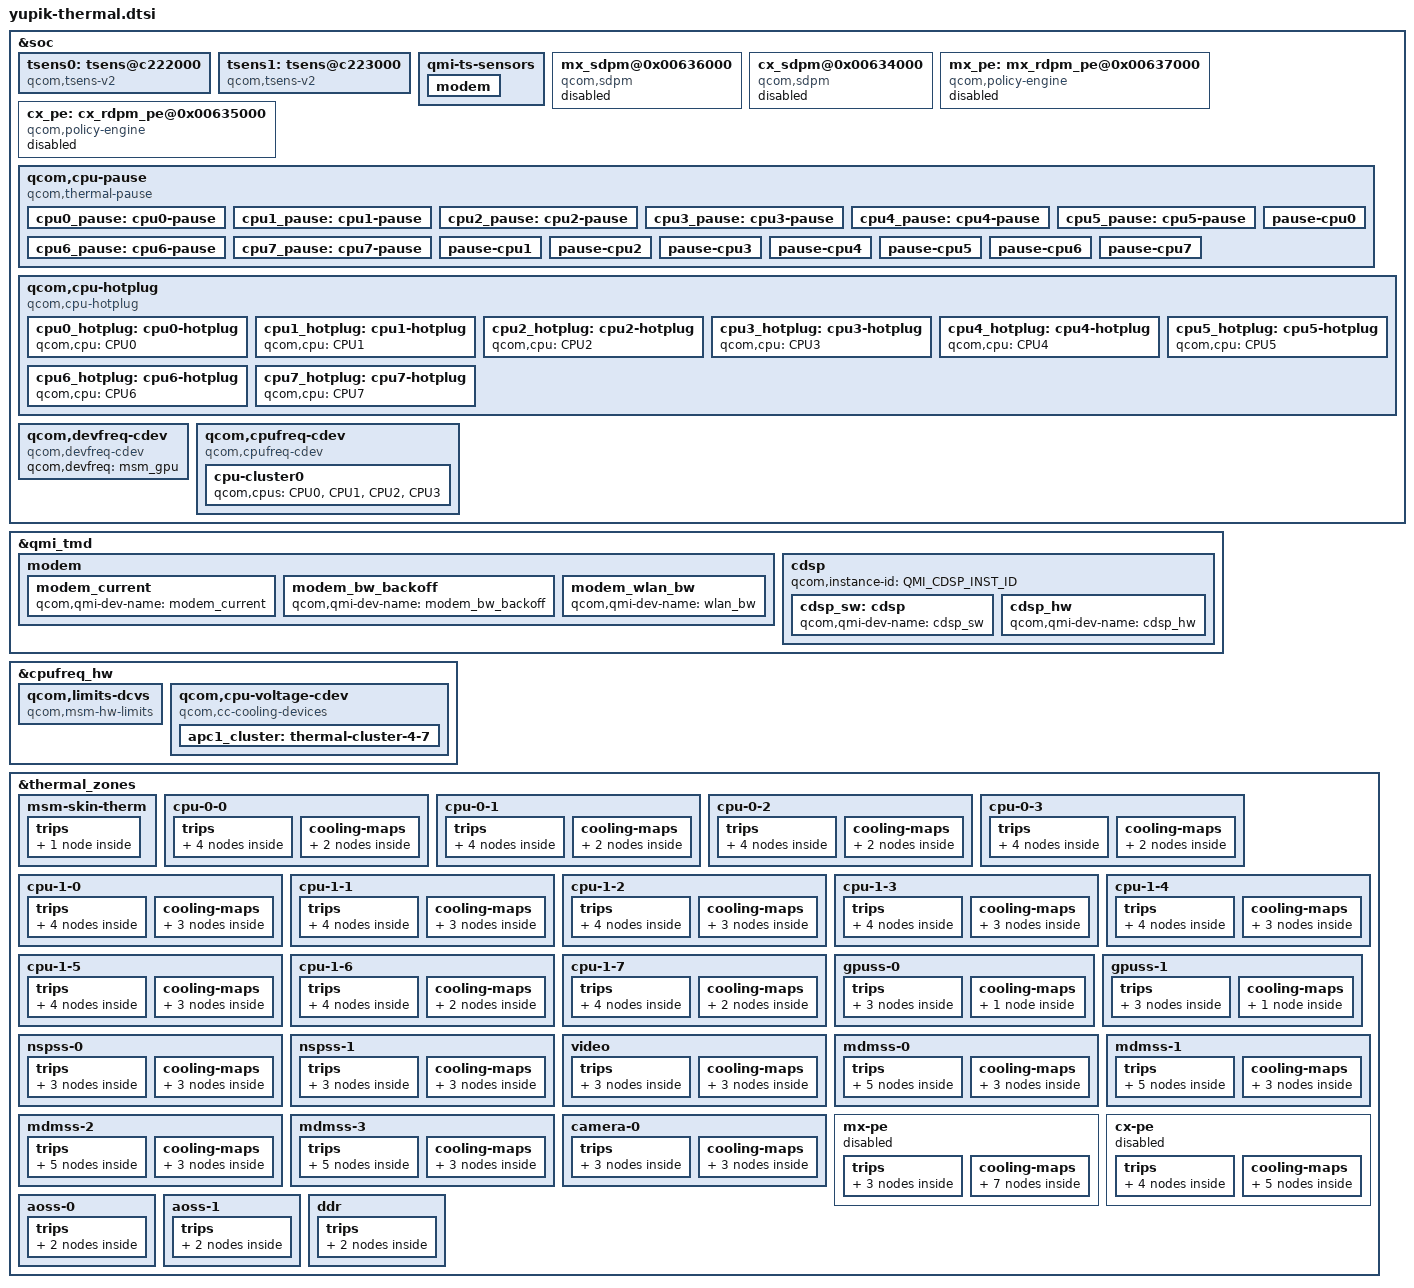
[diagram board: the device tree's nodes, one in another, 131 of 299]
// SPDX-License-Identifier: BSD-3-Clause
/*
 * Copyright (c) Qualcomm Technologies, Inc. and/or its subsidiaries.
 */

#include <dt-bindings/thermal/thermal_qti.h>
#include "lahaina-thermal-modem.dtsi"

&soc {
	tsens0:tsens@c222000 {
		compatible = "qcom,tsens-v2";
		reg = <0x0C263000 0x1ff>,
				<0x0C222000 0x8>;
		#qcom,sensors = <16>;
		interrupts = <GIC_SPI 506 IRQ_TYPE_LEVEL_HIGH>,
				<GIC_SPI 508 IRQ_TYPE_LEVEL_HIGH>;
		interrupt-names = "uplow","critical";
		#thermal-sensor-cells = <1>;
		nvmem-cells = <&tsens_chipinfo>;
		nvmem-cell-names = "tsens_chipinfo";
	};

	tsens1:tsens@c223000 {
		compatible = "qcom,tsens-v2";
		reg = <0x0C265000 0x1ff>,
				<0x0C223000 0x8>;
		#qcom,sensors = <16>;
		interrupts = <GIC_SPI 507 IRQ_TYPE_LEVEL_HIGH>,
				<GIC_SPI 509 IRQ_TYPE_LEVEL_HIGH>;
		interrupt-names = "uplow","critical";
		#thermal-sensor-cells = <1>;
		nvmem-cells = <&tsens_chipinfo>;
		nvmem-cell-names = "tsens_chipinfo";
	};

	qmi-ts-sensors {
		modem {
			qcom,qmi-sensor-names = "pa",
						"pa_1",
						"qfe_wtr0",
						"modem_tsens",
						"qfe_mmw0",
						"qfe_mmw1",
						"qfe_mmw2",
						"qfe_mmw3",
						"xo_therm",
						"qfe_mmw_streamer0",
						"qfe_mmw0_mod",
						"qfe_mmw1_mod",
						"qfe_mmw2_mod",
						"qfe_mmw3_mod",
						"qfe_ret_pa0",
						"qfe_wtr_pa0",
						"qfe_wtr_pa1",
						"qfe_wtr_pa2",
						"qfe_wtr_pa3",
						"sys_therm1",
						"modem_tsens1",
						"mmw_pa1",
						"mmw_pa2",
						"mmw_pa3",
						"msm_skin_therm";
		};
	};

	mx_sdpm@0x00636000 {
		compatible = "qcom,sdpm";
		reg = <0x00636000 0x1000>;
		clock-names = "cam_cc_ipe", "disp_cc_mdss_mdp";
		clocks = <&camcc CAM_CC_IPE_0_CLK_SRC>,
			<&dispcc DISP_CC_MDSS_MDP_CLK_SRC>;
		cam_cc_ipe-supply = <&cam_cc_ipe_0_gdsc>;
		csr-id = <1 4>;
		status = "disabled";
	};

	cx_sdpm@0x00634000 {
		compatible = "qcom,sdpm";
		reg = <0x00634000 0x1000>;
		clock-names = "cam_cc_ipe", "disp_cc_mdss_mdp";
		clocks = <&camcc CAM_CC_IPE_0_CLK_SRC>,
			<&dispcc DISP_CC_MDSS_MDP_CLK_SRC>;
		cam_cc_ipe-supply = <&cam_cc_ipe_0_gdsc>;
		csr-id = <0 2>;
		status = "disabled";
	};

	mx_pe: mx_rdpm_pe@0x00637000 {
		compatible = "qcom,policy-engine";
		#thermal-sensor-cells = <0>;
		reg = <0x00637000 0x1000>;
		interrupts = <GIC_SPI 237 IRQ_TYPE_LEVEL_HIGH>;
		status = "disabled";
	};

	cx_pe: cx_rdpm_pe@0x00635000 {
		compatible = "qcom,policy-engine";
		#thermal-sensor-cells = <0>;
		reg = <0x00635000 0x1000>;
		interrupts = <GIC_SPI 243 IRQ_TYPE_LEVEL_HIGH>;
		status = "disabled";
	};

	qcom,cpu-pause {
		compatible = "qcom,thermal-pause";
		cpu0_pause: cpu0-pause {

			qcom,cpus = <&CPU0>;
			qcom,cdev-alias = "thermal-pause-1";
			#cooling-cells = <2>;
		};

		cpu1_pause: cpu1-pause {
			qcom,cpus = <&CPU1>;
			qcom,cdev-alias = "thermal-pause-2";
			#cooling-cells = <2>;
		};

		cpu2_pause: cpu2-pause {
			qcom,cpus = <&CPU2>;
			qcom,cdev-alias = "thermal-pause-4";
			#cooling-cells = <2>;
		};

		cpu3_pause: cpu3-pause {
			qcom,cpus = <&CPU3>;
			qcom,cdev-alias = "thermal-pause-8";
			#cooling-cells = <2>;
		};

		cpu4_pause: cpu4-pause {
			qcom,cpus = <&CPU4>;
			qcom,cdev-alias = "thermal-pause-10";
			#cooling-cells = <2>;
		};

		cpu5_pause: cpu5-pause {
			qcom,cpus = <&CPU5>;
			qcom,cdev-alias = "thermal-pause-20";
			#cooling-cells = <2>;
		};

		cpu6_pause: cpu6-pause {
			qcom,cpus = <&CPU6>;
			qcom,cdev-alias = "thermal-pause-40";
			#cooling-cells = <2>;
		};

		cpu7_pause: cpu7-pause {
			qcom,cpus = <&CPU7>;
			qcom,cdev-alias = "thermal-pause-80";
			#cooling-cells = <2>;
		};

		/* Thermal-engine cooling devices */
		pause-cpu0 {
			qcom,cpus = <&CPU0>;
			qcom,cdev-alias = "pause-cpu0";
		};

		pause-cpu1 {
			qcom,cpus = <&CPU1>;
			qcom,cdev-alias = "pause-cpu1";
		};

		pause-cpu2 {
			qcom,cpus = <&CPU2>;
			qcom,cdev-alias = "pause-cpu2";
		};

		pause-cpu3 {
			qcom,cpus = <&CPU3>;
			qcom,cdev-alias = "pause-cpu3";
		};

		pause-cpu4 {
			qcom,cpus = <&CPU4>;
			qcom,cdev-alias = "pause-cpu4";
		};

		pause-cpu5 {
			qcom,cpus = <&CPU5>;
			qcom,cdev-alias = "pause-cpu5";
		};

		pause-cpu6 {
			qcom,cpus = <&CPU6>;
			qcom,cdev-alias = "pause-cpu6";
		};

		pause-cpu7 {
			qcom,cpus = <&CPU7>;
			qcom,cdev-alias = "pause-cpu7";
		};
	};

	qcom,cpu-hotplug {
		compatible = "qcom,cpu-hotplug";
		cpu0_hotplug: cpu0-hotplug {
			qcom,cpu = <&CPU0>;
			#cooling-cells = <2>;
		};

		cpu1_hotplug: cpu1-hotplug {
			qcom,cpu = <&CPU1>;
			#cooling-cells = <2>;
		};

		cpu2_hotplug: cpu2-hotplug {
			qcom,cpu = <&CPU2>;
			#cooling-cells = <2>;
		};

		cpu3_hotplug: cpu3-hotplug {
			qcom,cpu = <&CPU3>;
			#cooling-cells = <2>;
		};

		cpu4_hotplug: cpu4-hotplug {
			qcom,cpu = <&CPU4>;
			#cooling-cells = <2>;
		};

		cpu5_hotplug: cpu5-hotplug {
			qcom,cpu = <&CPU5>;
			#cooling-cells = <2>;
		};

		cpu6_hotplug: cpu6-hotplug {
			qcom,cpu = <&CPU6>;
			#cooling-cells = <2>;
		};

		cpu7_hotplug: cpu7-hotplug {
			qcom,cpu = <&CPU7>;
			#cooling-cells = <2>;
		};
	};

	qcom,devfreq-cdev {
		compatible = "qcom,devfreq-cdev";
		qcom,devfreq = <&msm_gpu>;
	};

	qcom,cpufreq-cdev {
		compatible = "qcom,cpufreq-cdev";
		cpu-cluster0 {
			qcom,cpus = <&CPU0 &CPU1 &CPU2 &CPU3>;
		};
	};
};

&qmi_tmd {
	modem {
		modem_current: modem_current {
			qcom,qmi-dev-name = "modem_current";
			#cooling-cells = <2>;
		};

		modem_bw_backoff: modem_bw_backoff {
			qcom,qmi-dev-name = "modem_bw_backoff";
			#cooling-cells = <2>;
		};

		modem_wlan_bw: modem_wlan_bw {
			qcom,qmi-dev-name = "wlan_bw";
			#cooling-cells = <2>;
		};
	};

	cdsp {
		qcom,instance-id = <QMI_CDSP_INST_ID>;

		cdsp_sw: cdsp {
			qcom,qmi-dev-name = "cdsp_sw";
			#cooling-cells = <2>;
		};

		cdsp_hw: cdsp_hw {
			qcom,qmi-dev-name = "cdsp_hw";
			#cooling-cells = <2>;
		};
	};
};

&cpufreq_hw {
	qcom,limits-dcvs {
		compatible = "qcom,msm-hw-limits";
		isens_vref_0p8-supply = <&pm8350c_l10_ao>;
		isens-vref-0p8-settings = <880000 880000 30000>;
		isens_vref_1p8-supply = <&pm8350c_l1_ao>;
		isens-vref-1p8-settings = <1800000 1800000 20000>;
	};

	qcom,cpu-voltage-cdev {
		compatible = "qcom,cc-cooling-devices";
		apc1_cluster: thermal-cluster-4-7 {
			qcom,cluster0 = <&CPU4 &CPU5 &CPU6>;
			qcom,cluster1 = <&CPU7>;
			#cooling-cells = <2>;
		};
	};
};

&thermal_zones {
	/delete-node/ modem-sdr-mmw-usr;
	/delete-node/ modem-ambient-usr;
	/delete-node/ mdmss-1;
	/delete-node/ mdmss-2;

	msm-skin-therm {
		polling-delay-passive = <0>;
		polling-delay = <0>;
		thermal-sensors = <&qmi_sensor
				(QMI_MODEM_INST_ID+QMI_QTM_THERM)>;
		trips {
			active-config0 {
				temperature = <125000>;
				hysteresis = <1000>;
				type = "passive";
			};
		};
	};

	cpu-0-0 {
		polling-delay-passive = <0>;
		polling-delay = <0>;
		thermal-sensors = <&tsens0 1>;
		trips {
			active-config0 {
				temperature = <125000>;
				hysteresis = <1000>;
				type = "passive";
			};

			reset-mon-cfg {
				temperature = <115000>;
				hysteresis = <5000>;
				type = "passive";
			};

			cpu00_config: cpu00-config {
				temperature = <110000>;
				hysteresis = <10000>;
				type = "passive";
			};

			cpu00_config1: cpu00-config1 {
				temperature = <112000>;
				hysteresis = <12000>;
				type = "passive";
			};
		};

		cooling-maps {
			cpu00_cdev {
				trip = <&cpu00_config>;
				cooling-device = <&cpu0_pause 0 1>;
			};

			cpu00_cdev2 {
				trip = <&cpu00_config1>;
				cooling-device = <&cpu0_hotplug 0 1>;
			};
		};
	};

	cpu-0-1 {
		polling-delay-passive = <0>;
		polling-delay = <0>;
		thermal-sensors = <&tsens0 2>;
		trips {
			active-config0 {
				temperature = <125000>;
				hysteresis = <1000>;
				type = "passive";
			};

			reset-mon-cfg {
				temperature = <115000>;
				hysteresis = <5000>;
				type = "passive";
			};

			cpu01_config: cpu01-config {
				temperature = <110000>;
				hysteresis = <10000>;
				type = "passive";
			};

			cpu01_config1: cpu01-config1 {
				temperature = <112000>;
				hysteresis = <12000>;
				type = "passive";
			};
		};

		cooling-maps {
			cpu01_cdev {
				trip = <&cpu01_config>;
				cooling-device = <&cpu1_pause 0 1>;
			};

			cpu01_cdev2 {
				trip = <&cpu01_config1>;
				cooling-device = <&cpu1_hotplug 0 1>;
			};
		};
	};

	cpu-0-2 {
		polling-delay-passive = <0>;
		polling-delay = <0>;
		thermal-sensors = <&tsens0 3>;
		trips {
			active-config0 {
				temperature = <125000>;
				hysteresis = <1000>;
				type = "passive";
			};

			reset-mon-cfg {
				temperature = <115000>;
				hysteresis = <5000>;
				type = "passive";
			};

			cpu02_config: cpu02-config {
				temperature = <110000>;
				hysteresis = <10000>;
				type = "passive";
			};

			cpu02_config1: cpu02-config1 {
				temperature = <112000>;
				hysteresis = <12000>;
				type = "passive";
			};
		};

		cooling-maps {
			cpu02_cdev {
				trip = <&cpu02_config>;
				cooling-device = <&cpu2_pause 0 1>;
			};

			cpu02_cdev2 {
				trip = <&cpu02_config1>;
				cooling-device = <&cpu2_hotplug 0 1>;
			};
		};
	};

	cpu-0-3 {
		polling-delay-passive = <0>;
		polling-delay = <0>;
		thermal-sensors = <&tsens0 4>;
		trips {
			active-config0 {
				temperature = <125000>;
				hysteresis = <1000>;
				type = "passive";
			};

			reset-mon-cfg {
				temperature = <115000>;
				hysteresis = <5000>;
				type = "passive";
			};

			cpu03_config: cpu03-config {
				temperature = <110000>;
				hysteresis = <10000>;
				type = "passive";
			};

			cpu03_config1: cpu03-config1 {
				temperature = <112000>;
				hysteresis = <12000>;
				type = "passive";
			};
		};

		cooling-maps {
			cpu03_cdev {
				trip = <&cpu03_config>;
				cooling-device = <&cpu3_pause 0 1>;
			};

			cpu03_cdev2 {
				trip = <&cpu03_config1>;
				cooling-device = <&cpu3_hotplug 0 1>;
			};
		};
	};

	cpu-1-0 {
		polling-delay-passive = <0>;
		polling-delay = <0>;
		thermal-sensors = <&tsens0 7>;
		trips {
			active-config0 {
				temperature = <125000>;
				hysteresis = <1000>;
				type = "passive";
			};

			reset-mon-cfg {
				temperature = <115000>;
				hysteresis = <5000>;
				type = "passive";
			};

			cpu10_config: cpu10-config {
				temperature = <108000>;
				hysteresis = <8000>;
				type = "passive";
			};

			cpu10_config1: cpu10-config1 {
				temperature = <110000>;
				hysteresis = <10000>;
				type = "passive";
			};
		};

		cooling-maps {
			cpu10_cdev {
				trip = <&cpu10_config>;
				cooling-device = <&cpu4_pause 0 1>;
			};

			cpu10_cdev1 {
				trip = <&cpu10_config>;
				cooling-device = <&apc1_cluster 0 THERMAL_NO_LIMIT>;
			};

			cpu10_cdev2 {
				trip = <&cpu10_config1>;
				cooling-device = <&cpu4_hotplug 0 1>;
			};
		};
	};

	cpu-1-1 {
		polling-delay-passive = <0>;
		polling-delay = <0>;
		thermal-sensors = <&tsens0 8>;
		trips {
			active-config0 {
				temperature = <125000>;
				hysteresis = <1000>;
				type = "passive";
			};

			reset-mon-cfg {
				temperature = <115000>;
				hysteresis = <5000>;
				type = "passive";
			};

			cpu11_config: cpu11-config {
				temperature = <108000>;
				hysteresis = <8000>;
				type = "passive";
			};

			cpu11_config1: cpu11-config1 {
				temperature = <110000>;
				hysteresis = <10000>;
				type = "passive";
			};
		};

		cooling-maps {
			cpu11_cdev {
				trip = <&cpu11_config>;
				cooling-device = <&cpu4_pause 0 1>;
			};

			cpu11_cdev1 {
				trip = <&cpu11_config>;
				cooling-device = <&apc1_cluster 0 THERMAL_NO_LIMIT>;
			};

			cpu11_cdev2 {
				trip = <&cpu11_config1>;
				cooling-device = <&cpu4_hotplug 0 1>;
			};
		};
	};

	cpu-1-2 {
		polling-delay-passive = <0>;
		polling-delay = <0>;
		thermal-sensors = <&tsens0 9>;
		trips {
			active-config0 {
				temperature = <125000>;
				hysteresis = <1000>;
				type = "passive";
			};

			reset-mon-cfg {
				temperature = <115000>;
				hysteresis = <5000>;
				type = "passive";
			};

			cpu12_config: cpu12-config {
				temperature = <108000>;
				hysteresis = <8000>;
				type = "passive";
			};

			cpu12_config1: cpu12-config1 {
				temperature = <110000>;
				hysteresis = <10000>;
				type = "passive";
			};
		};

		cooling-maps {
			cpu12_cdev {
				trip = <&cpu12_config>;
				cooling-device = <&cpu5_pause 0 1>;
			};

			cpu12_cdev1 {
				trip = <&cpu12_config>;
				cooling-device = <&apc1_cluster 0 THERMAL_NO_LIMIT>;
			};

			cpu12_cdev2 {
				trip = <&cpu12_config1>;
				cooling-device = <&cpu5_hotplug 0 1>;
			};
		};
	};

	cpu-1-3 {
		polling-delay-passive = <0>;
		polling-delay = <0>;
		thermal-sensors = <&tsens0 10>;
		trips {
			active-config0 {
				temperature = <125000>;
				hysteresis = <1000>;
				type = "passive";
			};

			reset-mon-cfg {
				temperature = <115000>;
				hysteresis = <5000>;
				type = "passive";
			};

			cpu13_config: cpu13-config {
				temperature = <108000>;
				hysteresis = <8000>;
				type = "passive";
			};

			cpu13_config1: cpu13-config1 {
				temperature = <110000>;
				hysteresis = <10000>;
				type = "passive";
			};
		};

		cooling-maps {
			cpu13_cdev {
				trip = <&cpu13_config>;
				cooling-device = <&cpu5_pause 0 1>;
			};

			cpu13_cdev1 {
				trip = <&cpu13_config>;
				cooling-device = <&apc1_cluster 0 THERMAL_NO_LIMIT>;
			};

			cpu13_cdev2 {
				trip = <&cpu13_config1>;
				cooling-device = <&cpu5_hotplug 0 1>;
			};
		};
	};

	cpu-1-4 {
		polling-delay-passive = <0>;
		polling-delay = <0>;
		thermal-sensors = <&tsens0 11>;
		trips {
			active-config0 {
				temperature = <125000>;
				hysteresis = <1000>;
				type = "passive";
			};

			reset-mon-cfg {
				temperature = <115000>;
				hysteresis = <5000>;
				type = "passive";
			};

			cpu14_config: cpu14-config {
				temperature = <108000>;
				hysteresis = <8000>;
				type = "passive";
			};

			cpu14_config1: cpu14-config1 {
				temperature = <110000>;
				hysteresis = <10000>;
				type = "passive";
			};
		};

		cooling-maps {
			cpu14_cdev {
				trip = <&cpu14_config>;
				cooling-device = <&cpu6_pause 0 1>;
			};

			cpu14_cdev1 {
				trip = <&cpu14_config>;
				cooling-device = <&apc1_cluster 0 THERMAL_NO_LIMIT>;
			};

			cpu14_cdev2 {
				trip = <&cpu14_config1>;
				cooling-device = <&cpu6_hotplug 0 1>;
			};
		};
	};

	cpu-1-5 {
		polling-delay-passive = <0>;
		polling-delay = <0>;
		thermal-sensors = <&tsens0 12>;
		trips {
			active-config0 {
				temperature = <125000>;
				hysteresis = <1000>;
				type = "passive";
			};

			reset-mon-cfg {
				temperature = <115000>;
				hysteresis = <5000>;
				type = "passive";
			};

			cpu15_config: cpu15-config {
				temperature = <108000>;
				hysteresis = <8000>;
				type = "passive";
			};

			cpu15_config1: cpu15-config1 {
				temperature = <110000>;
				hysteresis = <10000>;
				type = "passive";
			};
		};

		cooling-maps {
			cpu15_cdev {
				trip = <&cpu15_config>;
				cooling-device = <&cpu6_pause 0 1>;
			};

			cpu15_cdev1 {
				trip = <&cpu15_config>;
				cooling-device = <&apc1_cluster 0 THERMAL_NO_LIMIT>;
			};

			cpu15_cdev2 {
				trip = <&cpu15_config1>;
				cooling-device = <&cpu6_hotplug 0 1>;
			};
		};
	};

	cpu-1-6 {
		polling-delay-passive = <0>;
		polling-delay = <0>;
		thermal-sensors = <&tsens0 13>;
		trips {
			active-config0 {
				temperature = <125000>;
				hysteresis = <1000>;
				type = "passive";
			};

			reset-mon-cfg {
				temperature = <115000>;
				hysteresis = <5000>;
				type = "passive";
			};

			cpu16_config: cpu16-config {
				temperature = <108000>;
				hysteresis = <8000>;
				type = "passive";
			};

			cpu16_config1: cpu16-config1 {
				temperature = <110000>;
				hysteresis = <10000>;
				type = "passive";
			};
		};

		cooling-maps {
			cpu16_cdev {
				trip = <&cpu16_config>;
				cooling-device = <&cpu7_pause 0 1>;
			};

			cpu16_cdev2 {
				trip = <&cpu16_config1>;
				cooling-device = <&cpu7_hotplug 0 1>;
			};
		};
	};

	cpu-1-7 {
		polling-delay-passive = <0>;
		polling-delay = <0>;
		thermal-sensors = <&tsens0 14>;
		trips {
			active-config0 {
				temperature = <125000>;
				hysteresis = <1000>;
				type = "passive";
			};

			reset-mon-cfg {
				temperature = <115000>;
				hysteresis = <5000>;
				type = "passive";
			};

			cpu17_config: cpu17-config {
				temperature = <108000>;
				hysteresis = <8000>;
				type = "passive";
			};

			cpu17_config1: cpu17-config1 {
				temperature = <110000>;
				hysteresis = <10000>;
				type = "passive";
			};
		};

		cooling-maps {
			cpu17_cdev {
				trip = <&cpu17_config>;
				cooling-device = <&cpu7_pause 0 1>;
			};

			cpu17_cdev2 {
				trip = <&cpu17_config1>;
				cooling-device = <&cpu7_hotplug 0 1>;
			};
		};
	};

	gpuss-0 {
		polling-delay-passive = <10>;
		polling-delay = <0>;
		thermal-sensors = <&tsens1 1>;
		trips {
			active-config0 {
				temperature = <125000>;
				hysteresis = <1000>;
				type = "passive";
			};

			reset-mon-cfg {
				temperature = <115000>;
				hysteresis = <5000>;
				type = "passive";
			};

			gpuss0_config: active-config1 {
				temperature = <95000>;
				hysteresis = <0>;
				type = "passive";
			};
		};

		cooling-maps {
			gpu_cdev {
				trip = <&gpuss0_config>;
				cooling-device = <&msm_gpu 0 THERMAL_NO_LIMIT>;
			};
		};
	};

	gpuss-1 {
		polling-delay-passive = <10>;
		polling-delay = <100>;
		thermal-sensors = <&tsens1 2>;
		trips {
			active-config0 {
				temperature = <125000>;
				hysteresis = <1000>;
				type = "passive";
			};

			reset-mon-cfg {
				temperature = <115000>;
				hysteresis = <5000>;
				type = "passive";
			};

			gpuss1_config: active-config1 {
				temperature = <95000>;
				hysteresis = <0>;
				type = "passive";
			};
		};

		cooling-maps {
			gpu_cdev {
				trip = <&gpuss1_config>;
				cooling-device = <&msm_gpu 0 THERMAL_NO_LIMIT>;
			};
		};
	};

	nspss-0 {
		polling-delay-passive = <0>;
		polling-delay = <0>;
		thermal-sensors = <&tsens1 3>;
		trips {
			active-config0 {
				temperature = <125000>;
				hysteresis = <1000>;
				type = "passive";
			};

			reset-mon-cfg {
				temperature = <115000>;
				hysteresis = <5000>;
				type = "passive";
			};

			nspss0_trip: nspss0-trip {
				temperature = <100000>;
				hysteresis = <5000>;
				type = "passive";
			};
		};

		cooling-maps {
			cdsp_cdev {
				trip = <&nspss0_trip>;
				cooling-device = <&cdsp_sw 0 4>;
			};

			gpu_cdev {
				trip = <&nspss0_trip>;
				/* throttle to 315000000Hz */
				cooling-device = <&msm_gpu 0 THERMAL_NO_LIMIT>;
			};

			modem_pa_cdev {
				trip = <&nspss0_trip>;
				cooling-device = <&modem_pa 0 3>;
			};
		};
	};

	nspss-1 {
		polling-delay-passive = <0>;
		polling-delay = <0>;
		thermal-sensors = <&tsens1 4>;
		trips {
			active-config0 {
				temperature = <125000>;
				hysteresis = <1000>;
				type = "passive";
			};

			reset-mon-cfg {
				temperature = <115000>;
				hysteresis = <5000>;
				type = "passive";
			};

			nspss1_trip: nspss1-trip {
				temperature = <100000>;
				hysteresis = <5000>;
				type = "passive";
			};
		};

		cooling-maps {
			cdsp_cdev {
				trip = <&nspss1_trip>;
				cooling-device = <&cdsp_sw 0 4>;
			};

			gpu_cdev {
				trip = <&nspss1_trip>;
				/* throttle to 315000000Hz */
				cooling-device = <&msm_gpu 0 THERMAL_NO_LIMIT>;
			};

			modem_pa_cdev {
				trip = <&nspss1_trip>;
				cooling-device = <&modem_pa 0 3>;
			};
		};
	};

	video {
		polling-delay-passive = <0>;
		polling-delay = <0>;
		thermal-sensors = <&tsens1 5>;
		trips {
			active-config0 {
				temperature = <125000>;
				hysteresis = <1000>;
				type = "passive";
			};

			reset-mon-cfg {
				temperature = <115000>;
				hysteresis = <5000>;
				type = "passive";
			};

			video_trip: video-trip {
				temperature = <100000>;
				hysteresis = <5000>;
				type = "passive";
			};
		};

		cooling-maps {
			cdsp_cdev {
				trip = <&video_trip>;
				cooling-device = <&cdsp_sw 0 4>;
			};

			gpu_cdev {
				trip = <&video_trip>;
				/* throttle to 315000000Hz */
				cooling-device = <&msm_gpu 0 THERMAL_NO_LIMIT>;
			};

			modem_pa_cdev {
				trip = <&video_trip>;
				cooling-device = <&modem_pa 0 3>;
			};
		};
	};

	mdmss-0 {
		polling-delay-passive = <0>;
		polling-delay = <0>;
		thermal-sensors = <&tsens1 7>;
		trips {
			active-config0 {
				temperature = <125000>;
				hysteresis = <1000>;
				type = "passive";
			};

			reset-mon-cfg {
				temperature = <115000>;
				hysteresis = <5000>;
				type = "passive";
			};

			mdmss0_trip0: mdmss0-trip0 {
				temperature = <95000>;
				hysteresis = <15000>;
				type = "passive";
			};

			mdmss0_trip1: mdmss0-trip1 {
				temperature = <105000>;
				hysteresis = <15000>;
				type = "passive";
			};

			mdmss0_trip2: mdmss0-trip2 {
				temperature = <115000>;
				hysteresis = <15000>;
				type = "passive";
			};
		};

		cooling-maps {
			mdmss0_cdev0 {
				trip = <&mdmss0_trip0>;
				cooling-device = <&modem_tj 0 1>;
			};

			mdmss0_cdev1 {
				trip = <&mdmss0_trip1>;
				cooling-device = <&modem_tj 0 2>;
			};

			mdmss0_cdev2 {
				trip = <&mdmss0_trip2>;
				cooling-device = <&modem_tj 0 3>;
			};
		};
	};

	mdmss-1 {
		polling-delay-passive = <0>;
		polling-delay = <0>;
		thermal-sensors = <&tsens1 8>;
		trips {
			active-config0 {
				temperature = <125000>;
				hysteresis = <1000>;
				type = "passive";
			};

			reset-mon-cfg {
				temperature = <115000>;
				hysteresis = <5000>;
				type = "passive";
			};

			mdmss1_trip0: mdmss1-trip0 {
				temperature = <95000>;
				hysteresis = <15000>;
				type = "passive";
			};

			mdmss1_trip1: mdmss1-trip1 {
				temperature = <105000>;
				hysteresis = <15000>;
				type = "passive";
			};

			mdmss1_trip2: mdmss1-trip2 {
				temperature = <115000>;
				hysteresis = <15000>;
				type = "passive";
			};
		};

		cooling-maps {
			mdmss1_cdev0 {
				trip = <&mdmss1_trip0>;
				cooling-device = <&modem_tj 0 1>;
			};

			mdmss1_cdev1 {
				trip = <&mdmss1_trip1>;
				cooling-device = <&modem_tj 0 2>;
			};

			mdmss1_cdev2 {
				trip = <&mdmss1_trip2>;
				cooling-device = <&modem_tj 0 3>;
			};
		};
	};

	mdmss-2 {
		polling-delay-passive = <0>;
		polling-delay = <0>;
		thermal-sensors = <&tsens1 9>;
		trips {
			active-config0 {
				temperature = <125000>;
				hysteresis = <1000>;
				type = "passive";
			};

			reset-mon-cfg {
				temperature = <115000>;
				hysteresis = <5000>;
				type = "passive";
			};

			mdmss2_trip0: mdmss2-trip0 {
				temperature = <95000>;
				hysteresis = <15000>;
				type = "passive";
			};

			mdmss2_trip1: mdmss2-trip1 {
				temperature = <105000>;
				hysteresis = <15000>;
				type = "passive";
			};

			mdmss2_trip2: mdmss2-trip2 {
				temperature = <115000>;
				hysteresis = <15000>;
				type = "passive";
			};
		};

		cooling-maps {
			mdmss2_cdev0 {
				trip = <&mdmss2_trip0>;
				cooling-device = <&modem_tj 0 1>;
			};

			mdmss2_cdev1 {
				trip = <&mdmss2_trip1>;
				cooling-device = <&modem_tj 0 2>;
			};

			mdmss2_cdev2 {
				trip = <&mdmss2_trip2>;
				cooling-device = <&modem_tj 0 3>;
			};
		};
	};

	mdmss-3 {
		polling-delay-passive = <0>;
		polling-delay = <0>;
		thermal-sensors = <&tsens1 10>;
		trips {
			active-config0 {
				temperature = <125000>;
				hysteresis = <1000>;
				type = "passive";
			};

			reset-mon-cfg {
				temperature = <115000>;
				hysteresis = <5000>;
				type = "passive";
			};

			mdmss3_trip0: mdmss3-trip0 {
				temperature = <95000>;
				hysteresis = <15000>;
				type = "passive";
			};

			mdmss3_trip1: mdmss3-trip1 {
				temperature = <105000>;
				hysteresis = <15000>;
				type = "passive";
			};

			mdmss3_trip2: mdmss3-trip2 {
				temperature = <115000>;
				hysteresis = <15000>;
				type = "passive";
			};
		};

		cooling-maps {
			mdmss3_cdev0 {
				trip = <&mdmss3_trip0>;
				cooling-device = <&modem_tj 0 1>;
			};

			mdmss3_cdev1 {
				trip = <&mdmss3_trip1>;
				cooling-device = <&modem_tj 0 2>;
			};

			mdmss3_cdev2 {
				trip = <&mdmss3_trip2>;
				cooling-device = <&modem_tj 0 3>;
			};
		};
	};

	camera-0 {
		polling-delay-passive = <0>;
		polling-delay = <0>;
		thermal-sensors = <&tsens1 11>;
		trips {
			active-config0 {
				temperature = <125000>;
				hysteresis = <1000>;
				type = "passive";
			};

			reset-mon-cfg {
				temperature = <115000>;
				hysteresis = <5000>;
				type = "passive";
			};

			camera_trip: camera-trip {
				temperature = <100000>;
				hysteresis = <5000>;
				type = "passive";
			};
		};

		cooling-maps {
			cdsp_cdev {
				trip = <&camera_trip>;
				cooling-device = <&cdsp_sw 0 4>;
			};

			gpu_cdev {
				trip = <&camera_trip>;
				/* throttle to 315000000Hz */
				cooling-device = <&msm_gpu 0 THERMAL_NO_LIMIT>;
			};

			modem_pa_cdev {
				trip = <&camera_trip>;
				cooling-device = <&modem_pa 0 3>;
			};
		};
	};

	mx-pe {
		polling-delay-passive = <0>;
		polling-delay = <0>;
		thermal-sensors = <&mx_pe>;
		status = "disabled";
		trips {
			mx_pe_config1: mx-pe-config1 {
				temperature = <1>;
				hysteresis = <1>;
				type = "passive";
			};

			mx_pe_config2: mx-pe-config2 {
				temperature = <2>;
				hysteresis = <1>;
				type = "passive";
			};

			mx_pe_config3: mx-pe-config3 {
				temperature = <3>;
				hysteresis = <1>;
				type = "passive";
			};
		};

		cooling-maps {
			mx_pe_cdev_cpu4 {
				trip = <&mx_pe_config1>;
				cooling-device = <&cpu4_pause 0 1>;
			};

			mx_pe_cdev_cpu5 {
				trip = <&mx_pe_config1>;
				cooling-device = <&cpu5_pause 0 1>;
			};

			mx_pe_cdev_cpu6 {
				trip = <&mx_pe_config1>;
				cooling-device = <&cpu6_pause 0 1>;
			};

			mx_pe_cdev_cpu7 {
				trip = <&mx_pe_config1>;
				cooling-device = <&cpu7_pause 0 1>;
			};

			mx_pe_cdev_cdsp {
				trip = <&mx_pe_config1>;
				cooling-device = <&cdsp_sw 0 1>;
			};

			mx_pe_cdev_gpu {
				trip = <&mx_pe_config2>;
				cooling-device = <&msm_gpu 0 1>;
			};

			mx_pe_cdev_modem {
				trip = <&mx_pe_config3>;
				cooling-device = <&modem_tj 0 1>;
			};
		};
	};

	cx-pe {
		polling-delay-passive = <0>;
		polling-delay = <0>;
		thermal-sensors = <&cx_pe>;
		status = "disabled";
		trips {
			cx_pe_config1: cx-pe-config1 {
				temperature = <1>;
				hysteresis = <1>;
				type = "passive";
			};

			cx_pe_config2: cx-pe-config2 {
				temperature = <2>;
				hysteresis = <1>;
				type = "passive";
			};

			cx_pe_config3: cx-pe-config3 {
				temperature = <3>;
				hysteresis = <1>;
				type = "passive";
			};

			cx_pe_config4: cx-pe-config4 {
				temperature = <4>;
				hysteresis = <1>;
				type = "passive";
			};
		};

		cooling-maps {
			cx_pe_cdev_1 {
				trip = <&cx_pe_config1>;
				cooling-device = <&cdsp_sw 0 0>;
			};

			cx_pe_cdev_2 {
				trip = <&cx_pe_config2>;
				cooling-device = <&cdsp_sw 0 0>;
			};

			cx_pe_cdev_3 {
				trip = <&cx_pe_config3>;
				cooling-device = <&cdsp_sw 0 0>;
			};

			cx_pe_cdev_4 {
				trip = <&cx_pe_config4>;
				cooling-device = <&modem_tj 0 0>;
			};

			cx_pe_cdev_5 {
				trip = <&cx_pe_config4>;
				cooling-device = <&msm_gpu 0 0>;
			};
		};
	};

	aoss-0 {
		polling-delay-passive = <0>;
		polling-delay = <0>;
		thermal-sensors = <&tsens0 0>;
		trips {
			active-config0 {
				temperature = <125000>;
				hysteresis = <1000>;
				type = "passive";
			};

			reset-mon-cfg {
				temperature = <115000>;
				hysteresis = <5000>;
				type = "passive";
			};
		};
	};

	aoss-1 {
		polling-delay-passive = <0>;
		polling-delay = <0>;
		thermal-sensors = <&tsens1 0>;
		trips {
			active-config0 {
				temperature = <125000>;
				hysteresis = <1000>;
				type = "passive";
			};

			reset-mon-cfg {
				temperature = <115000>;
				hysteresis = <5000>;
				type = "passive";
			};
		};
	};

	ddr {
		polling-delay-passive = <0>;
		polling-delay = <0>;
		thermal-sensors = <&tsens1 6>;
		trips {
			active-config0 {
				temperature = <125000>;
				hysteresis = <1000>;
				type = "passive";
			};

			reset-mon-cfg {
				temperature = <115000>;
				hysteresis = <5000>;
				type = "passive";
			};
		};
	};
};
